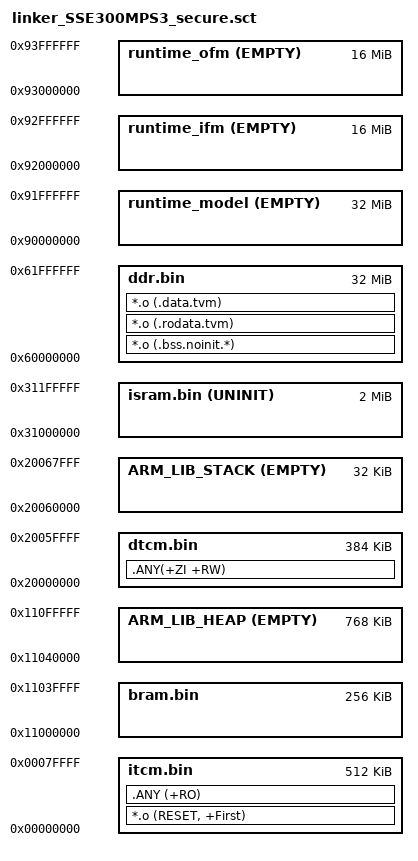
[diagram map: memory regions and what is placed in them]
#! armclang --target=arm-arm-none-eabi -march=armv8.1-m.main -E -xc

;/*
; * Copyright (c) 2018-2023 Arm Limited
; *
; * Licensed under the Apache License, Version 2.0 (the "License");
; * you may not use this file except in compliance with the License.
; * You may obtain a copy of the License at
; *
; *     http://www.apache.org/licenses/LICENSE-2.0
; *
; * Unless required by applicable law or agreed to in writing, software
; * distributed under the License is distributed on an "AS IS" BASIS,
; * WITHOUT WARRANTIES OR CONDITIONS OF ANY KIND, either express or implied.
; * See the License for the specific language governing permissions and
; * limitations under the License.
; *
; */

LOAD_REGION_0       0x00000000                  0x00080000
{
    ; ITCM is used for code
    itcm.bin        0x00000000                  0x00080000
    {
        *.o (RESET, +First)
        .ANY (+RO)
    }

    ; DTCM is used for any other RW or ZI data.
    dtcm.bin        0x20000000                  0x00060000
    {
        .ANY(+ZI +RW)
    }

    ; 32 kiB of stack space within the DTCM region.
    ARM_LIB_STACK   0x20060000 EMPTY ALIGN 8    0x00008000
    {}

    ; This region should have 3 cycle read latency from both Cortex-M55 and Ethos-U NPU
    isram.bin       0x31000000  UNINIT ALIGN 16 0x00200000
    {
    }
}

; Second load region (DDR)
LOAD_REGION_1       0x60000000                  0x02000000
{
    ; 32 MiB of DDR space for neural network model input vectors and labels.
    ddr.bin        0x60000000 ALIGN 16         0x02000000
    {
        *.o (.bss.noinit.*)
        *.o (.rodata.tvm)
        *.o (.data.tvm)
    }

    ; First 256kiB of BRAM (FPGA SRAM) used for RO data.
    bram.bin        0x11000000          ALIGN 8 0x00040000
    {
        ; RO data (incl. unwinding tables for debugging)
        ;.ANY (+RO-DATA)
    }

    ; 768 KiB of remaining part of the 1MiB BRAM used as heap space.
    ARM_LIB_HEAP    0x11040000 EMPTY ALIGN 8    0x000C0000
    {

    }

    ; 32 MiB of model space for run-time load of model
    runtime_model   0x90000000 EMPTY ALIGN 16   0x02000000
    {

    }

    ; 16 MiB of IFM space for run-time loading (FVP only)
    runtime_ifm     0x92000000 EMPTY ALIGN 16   0x01000000
    {}

    ; 16 MiB of OFM space for run-time loading (FVP only)
    runtime_ofm     0x93000000 EMPTY ALIGN 16   0x01000000
    {}
}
